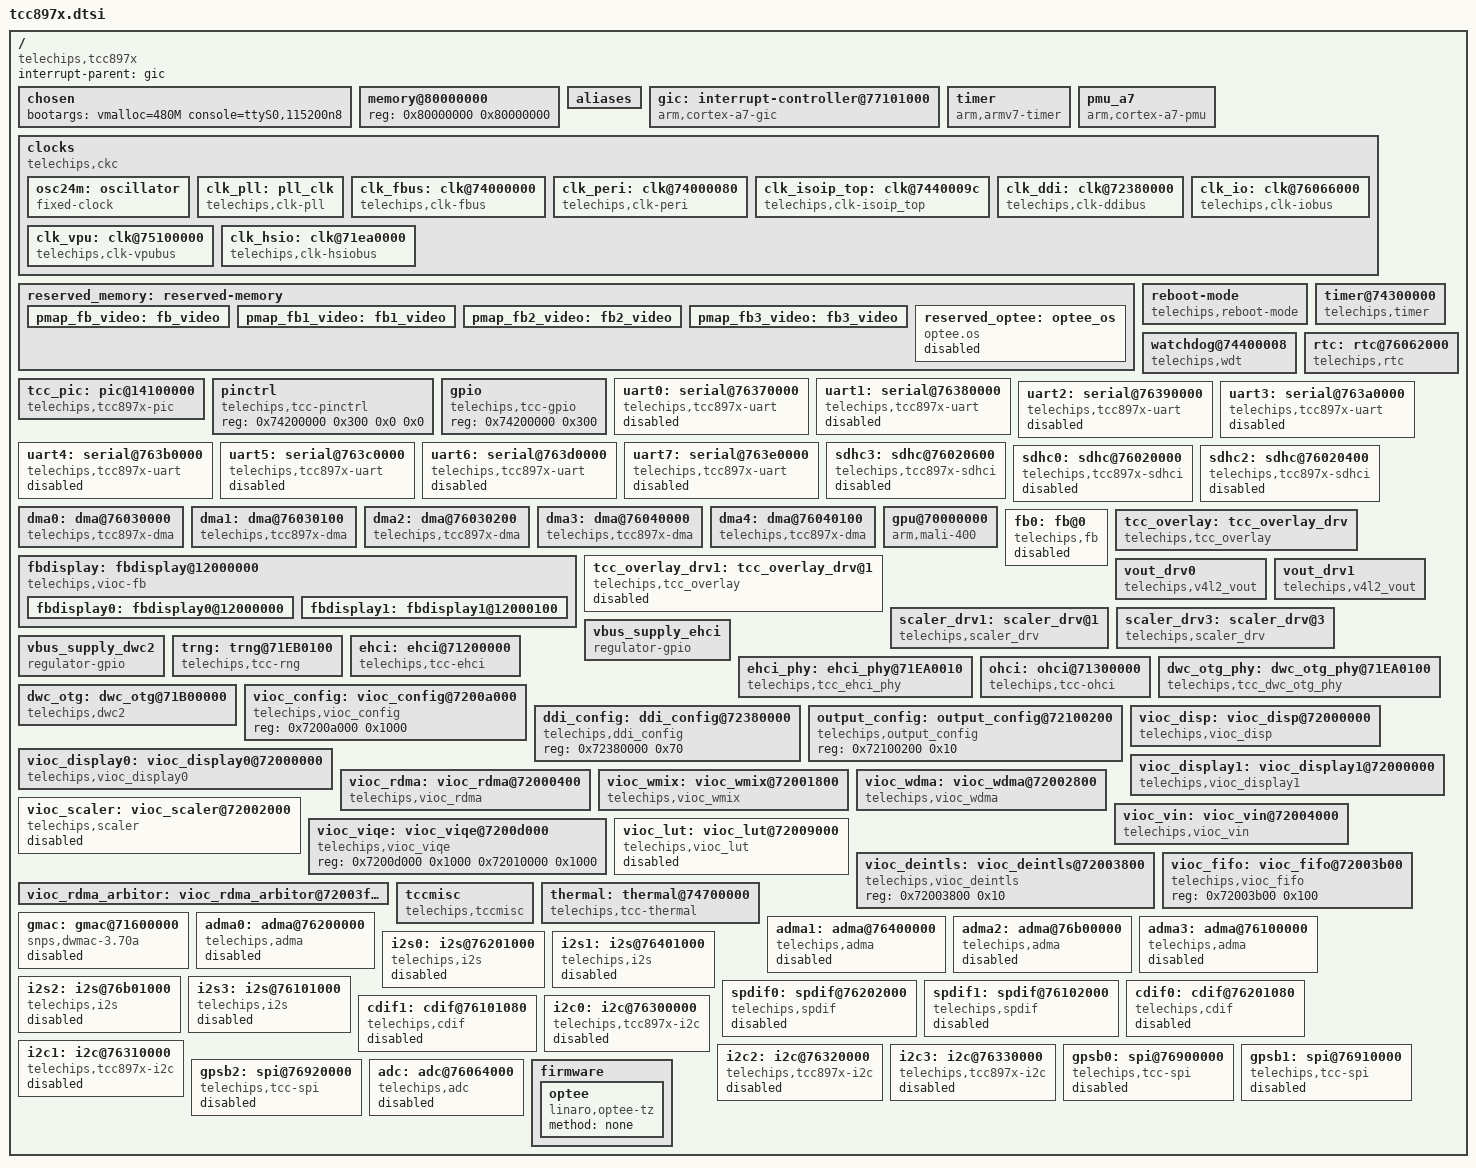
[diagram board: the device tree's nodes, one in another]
// SPDX-License-Identifier: (GPL-2.0-or-later OR MIT)
/*
 * Copyright (C) Telechips Inc.
 */

#include <dt-bindings/interrupt-controller/arm-gic.h>
#include <dt-bindings/clock/telechips,tcc897x-clks.h>
#include <dt-bindings/soc/tcc897x-pm.h>
#include <dt-bindings/display/tcc897x-vioc.h>
#include <dt-bindings/power/tcc897x,boot-mode.h>

/ {
	compatible = "telechips,tcc897x";
	interrupt-parent = <&gic>;
	#address-cells = <1>;
	#size-cells = <1>;

	chosen {
		bootargs = "vmalloc=480M console=ttyS0,115200n8";
	};

	memory@80000000 {
		#address-cells = <1>;
		#size-cells = <1>;
		device_type = "memory";
		reg = <0x80000000 0x80000000>;
	};

	aliases {
		serial0 = &uart0;
		serial1 = &uart1;
		serial2 = &uart2;
		serial3 = &uart3;
		serial4 = &uart4;
		serial5 = &uart5;
		serial6 = &uart6;
		serial7 = &uart7;
		sdhc0 = &sdhc0;
		sdhc2 = &sdhc2;
		sdhc3 = &sdhc3;
		scaler-drv1 = &scaler_drv1;
		scaler-drv3 = &scaler_drv3;
		tcc-overlay-drv1 = &tcc_overlay_drv1;
		vout-drv0 = &vout_drv0;
		vout-drv1 = &vout_drv1;
		dma0 = &dma0;
		dma1 = &dma1;
		dma2 = &dma2;
		dma3 = &dma3;
		dma4 = &dma4;
		fb0 = &fb0;
		adma0 = &adma0;
		adma1 = &adma1;
		adma2 = &adma2;
		adma3 = &adma3;
		i2s0 = &i2s0;
		i2s1 = &i2s1;
		i2s2 = &i2s2;
		i2s3 = &i2s3;
		spdif0 = &spdif0;
		spdif1 = &spdif1;
		cdif0 = &cdif0;
		cdif1 = &cdif1;
		gmac = &gmac;
		i2c0 = &i2c0;
		i2c1 = &i2c1;
		i2c2 = &i2c2;
		i2c3 = &i2c3;
		gpsb0 = &gpsb0;
		gpsb1 = &gpsb1;
		gpsb2 = &gpsb2;
		adc = &adc;
	};

	gic:interrupt-controller@77101000 {
		compatible = "arm,cortex-a7-gic";
		#interrupt-cells = <3>;
		#address-cells = <0>;
		interrupt-controller;
		reg = <0x77101000 0x1000>,
		      <0x77102000 0x1000>;
	};

	timer {
		compatible = "arm,armv7-timer";
		interrupts = <GIC_PPI 13 (GIC_CPU_MASK_SIMPLE(4) | IRQ_TYPE_LEVEL_LOW)>,
		             <GIC_PPI 14 (GIC_CPU_MASK_SIMPLE(4) | IRQ_TYPE_LEVEL_LOW)>,
		             <GIC_PPI 11 (GIC_CPU_MASK_SIMPLE(4) | IRQ_TYPE_LEVEL_LOW)>,
		             <GIC_PPI 10 (GIC_CPU_MASK_SIMPLE(4) | IRQ_TYPE_LEVEL_LOW)>;
		always-on;
	};

	pmu_a7 {
		compatible = "arm,cortex-a7-pmu";
		interrupts = <GIC_SPI 64 IRQ_TYPE_LEVEL_LOW>,
		             <GIC_SPI 65 IRQ_TYPE_LEVEL_LOW>,
		             <GIC_SPI 66 IRQ_TYPE_LEVEL_LOW>,
		             <GIC_SPI 67 IRQ_TYPE_LEVEL_LOW>;
	};

	clocks {
		compatible = "telechips,ckc";
		#address-cells = <1>;
		#size-cells = <1>;
		reg = <0x74000000 0x1A8	/* ckc */
		       0x74400000 0x114	/* pmu */
		       0x73810000 0x018	/* memory bus configutaion */
		       0x72380000 0x008	/* display bus configutaion */
		       0x70010000 0x008	/* graphic bus configutaion */
		       0x76066000 0x070	/* io bus configutaion */
		       0x75100000 0x008	/* video bus configutaion */
		       0x71EA0000 0x008	/* hsio bus configutaion */
		       >;
		ranges;

		osc24m: oscillator {
			compatible = "fixed-clock";
			#clock-cells = <0>;
			clock-frequency = <24000000>;
			clock-output-names = "osc24m";
		};

		clk_pll: pll_clk {
			compatible = "telechips,clk-pll";
			#clock-cells = <1>;
			clocks = <&osc24m>;
			clock-output-names = "pll0", "pll1", "pll2", "pll_cb",
					     "pll_mb";
		};

		clk_fbus: clk@74000000 {
			compatible = "telechips,clk-fbus";
			#clock-cells = <1>;
			clock-indices =
				<FBUS_CPU0>, <FBUS_CPU1>, <FBUS_MEM>, <FBUS_DDI>,
				<FBUS_GPU>, <FBUS_IO>, <FBUS_VBUS>, <FBUS_CODA>,
				<FBUS_HSIO>, <FBUS_SMU>, <FBUS_G2D>, <FBUS_CMBUS>,
				<FBUS_HEVC_VCE>, <FBUS_HEVC_VCPU>,
				<FBUS_HEVC_BPU>;
			clock-output-names =
				"fbus_cpu0", "fbus_cpu1", "fbus_mem", "fbus_ddi",
				"fbus_gpu", "fbus_io", "fbus_vbus", "fbus_coda",
				"fbus_hsio", "fbus_smu", "fbus_g2d", "fbus_cmbus",
				"fbus_hevc_vce", "fbus_hevc_vcpu",
				"fbus_hevc_bpu";
			telechips,clock-flags =
				<0>,	/* FBUS_CPU0 */
				<0>,	/* FBUS_CPU1 */
				<(CLK_SET_RATE_GATE | CLK_IGNORE_UNUSED)>,	/* FBUS_MEM */
				<(CLK_SET_RATE_GATE | CLK_IGNORE_UNUSED)>,	/* FBUS_DDI */
				<(CLK_SET_RATE_GATE | CLK_IGNORE_UNUSED)>,	/* FBUS_GPU */
				<(CLK_SET_RATE_GATE | CLK_IGNORE_UNUSED)>,	/* FBUS_IO */
				<(CLK_SET_RATE_GATE | CLK_IGNORE_UNUSED)>,	/* FBUS_VBUS */
				<(CLK_SET_RATE_GATE | CLK_IGNORE_UNUSED)>,	/* FBUS_CODA */
				<(CLK_SET_RATE_GATE | CLK_IGNORE_UNUSED)>,	/* FBUS_HSIO */
				<(CLK_SET_RATE_GATE | CLK_IGNORE_UNUSED)>,	/* FBUS_SMU */
				<(CLK_SET_RATE_GATE | CLK_IGNORE_UNUSED)>,	/* FBUS_G2D */
				<CLK_IGNORE_UNUSED>,	/* FBUS_CMBUS */
				<(CLK_SET_RATE_GATE | CLK_IGNORE_UNUSED)>,	/* FBUS_HEVC_VCE */
				<(CLK_SET_RATE_GATE | CLK_IGNORE_UNUSED)>,	/* FBUS_HEVC_VCPU */
				<(CLK_SET_RATE_GATE | CLK_IGNORE_UNUSED)>;	/* FBUS_HEVC_BPU */
		};

		clk_peri: clk@74000080 {
			compatible = "telechips,clk-peri";
			#clock-cells = <1>;
			clock-indices =
				<PERI_TCX>, <PERI_TCT>, <PERI_TCZ>, <PERI_LCD0>,
				<PERI_LCDSI0>, <PERI_LCD1>, <PERI_LCDSI1>,
				<PERI_LCDTIMER>, <PERI_USB_OTG>,
				<PERI_GMAC_PTP>, <PERI_GMAC>, <PERI_USB_OTG_ADP>,
				<PERI_IOB_CEC>, <PERI_OUT0>, <PERI_HDMI>,
				<PERI_HDMIA>, <PERI_OUT1>, <PERI_REMOTE>,
				<PERI_SDMMC0>, <PERI_SDMMC1>, <PERI_SDMMC2>,
				<PERI_SDMMC3>, <PERI_ADAI3>, <PERI_ADAM3>,
				<PERI_SPDIF3>, <PERI_ADAI0>, <PERI_ADAM0>,
				<PERI_SPDIF0>, <PERI_PDM>, <PERI_CMBUS_CNT>,
				<PERI_ADC>, <PERI_I2C0>, <PERI_I2C1>, <PERI_I2C2>,
				<PERI_I2C3>, <PERI_UART0>, <PERI_UART1>,
				<PERI_UART2>, <PERI_UART3>, <PERI_UART4>,
				<PERI_UART5>, <PERI_UART6>, <PERI_UART7>,
				<PERI_GPSB0>, <PERI_GPSB1>, <PERI_GPSB2>,
				<PERI_I2C6>, <PERI_I2C7>, <PERI_OUT2>, <PERI_OUT3>,
				<PERI_OUT4>, <PERI_OUT5>, <PERI_TSTX0>,
				<PERI_CMBUS_TSIF0>, <PERI_CMBUS_TSIF1>,
				<PERI_CMBUS_TSIF2>, <PERI_CMBUS_TSIF3>, <PERI_I2C4>,
				<PERI_I2C5>, <PERI_HDMI_PCLK>, <PERI_ADAI1>,
				<PERI_ADAM1>, <PERI_SPDIF1>, <PERI_ADAI2>,
				<PERI_ADAM2>, <PERI_SPDIF2>;
			clock-output-names =
				"peri_tcx", "peri_tct", "peri_tcz", "peri_lcd0",
				"peri_lcdsi0", "peri_lcd1", "peri_lcdsi1",
				"peri_lcdtimer", "peri_usb_otg",
				"peri_gmac_ptp", "peri_gmac", "peri_usb_otg_adp",
				"peri_iob_cec", "peri_out0", "peri_hdmi",
				"peri_hdmia", "peri_out1", "peri_remote",
				"peri_sdmmc0", "peri_sdmmc1", "peri_sdmmc2",
				"peri_sdmmc3", "peri_adai3", "peri_adam3",
				"peri_spdif3", "peri_adai0", "peri_adam0",
				"peri_spdif0", "peri_pdm", "peri_cmbus_cnt",
				"peri_adc", "peri_i2c0", "peri_i2c1", "peri_i2c2",
				"peri_i2c3", "peri_uart0", "peri_uart1",
				"peri_uart2", "peri_uart3", "peri_uart4",
				"peri_uart5", "peri_uart6", "peri_uart7",
				"peri_gpsb0", "peri_gpsb1", "peri_gpsb2",
				"peri_i2c6", "peri_i2c7", "peri_out2", "peri_out3",
				"peri_out4", "peri_out5", "peri_tstx0",
				"peri_cmbus_tsif0", "peri_cmbus_tsif1",
				"peri_cmbus_tsif2", "peri_cmbus_tsif3", "peri_i2c4",
				"peri_i2c5", "peri_hdmi_pclk", "peri_adai1",
				"peri_adam1", "peri_spdif1", "peri_adai2",
				"peri_adam2", "peri_spdif2";
			telechips,clock-flags =
				<0>,	/* PERI_TCX */
				<0>,	/* PERI_TCT */
				<CLK_IGNORE_UNUSED>,	/* PERI_TCZ */
				<0>,	/* PERI_LCD0 */
				<0>,	/* PERI_LCDSI0 */
				<0>,	/* PERI_LCD1 */
				<0>,	/* PERI_LCDSI1 */
				<0>,	/* PERI_LCDTIMER */
				<0>,	/* PERI_USB_OTG */
				<0>,	/* PERI_GMAC_PTP */
				<0>,	/* PERI_GMAC */
				<0>,	/* PERI_USB_OTG_ADP */
				<0>,	/* PERI_IOB_CEC */
				<0>,	/* PERI_OUT0 */
				<0>,	/* PERI_HDMI */
				<0>,	/* PERI_HDMIA */
				<0>,	/* PERI_OUT1 */
				<0>,	/* PERI_REMOTE */
				<0>,	/* PERI_SDMMC0 */
				<0>,	/* PERI_SDMMC1 */
				<0>,	/* PERI_SDMMC2 */
				<0>,	/* PERI_SDMMC3 */
				<0>,	/* PERI_ADAI3 */
				<0>,	/* PERI_ADAM3 */
				<0>,	/* PERI_SPDIF3 */
				<0>,	/* PERI_ADAI0 */
				<0>,	/* PERI_ADAM0 */
				<0>,	/* PERI_SPDIF0 */
				<0>,	/* PERI_PDM */
				<CLK_IGNORE_UNUSED>,	/* PERI_CMBUS_CNT */
				<0>,	/* PERI_ADC */
				<0>,	/* PERI_I2C0 */
				<0>,	/* PERI_I2C1 */
				<0>,	/* PERI_I2C2 */
				<0>,	/* PERI_I2C3 */
				<0>,	/* PERI_UART0 */
				<0>,	/* PERI_UART1 */
				<0>,	/* PERI_UART2 */
				<0>,	/* PERI_UART3 */
				<0>,	/* PERI_UART4 */
				<0>,	/* PERI_UART5 */
				<0>,	/* PERI_UART6 */
				<0>,	/* PERI_UART7 */
				<0>,	/* PERI_GPSB0 */
				<0>,	/* PERI_GPSB1 */
				<0>,	/* PERI_GPSB2 */
				<0>,	/* PERI_I2C6 */
				<0>,	/* PERI_I2C7 */
				<0>,	/* PERI_OUT2 */
				<0>,	/* PERI_OUT3 */
				<0>,	/* PERI_OUT4 */
				<0>,	/* PERI_OUT5 */
				<0>,	/* PERI_TSTX0 */
				<0>,	/* PERI_CMBUS_TSIF0 */
				<0>,	/* PERI_CMBUS_TSIF1 */
				<0>,	/* PERI_CMBUS_TSIF2 */
				<0>,	/* PERI_CMBUS_TSIF3 */
				<0>,	/* PERI_I2C4 */
				<0>,	/* PERI_I2C5 */
				<0>,	/* PERI_HDMI_PCLK */
				<CLK_IGNORE_UNUSED>,	/* PERI_ADAI1 */
				<CLK_IGNORE_UNUSED>,	/* PERI_ADAM1 */
				<0>,	/* PERI_SPDIF1 */
				<0>,	/* PERI_ADAI2 */
				<0>,	/* PERI_ADAM2 */
				<0>;	/* PERI_SPDIF2 */
		};

		clk_isoip_top: clk@7440009c {
			compatible = "telechips,clk-isoip_top";
			#clock-cells = <1>;
			clock-indices =
				<ISOIP_TOP_OTP>, <ISOIP_TOP_RTC>,
				<ISOIP_TOP_PLL>, <ISOIP_TOP_ECID>,
				<ISOIP_TOP_HDMI>, <ISOIP_TOP_VDAC_3CH>,
				<ISOIP_TOP_VDAC_1CH>, <ISOIP_TOP_TSADC>,
				<ISOIP_TOP_USB2P>, <ISOIP_TOP_USBOTG>,
				<ISOIP_TOP_LVDS>;
			clock-output-names =
				"isoip_top_otp", "isoip_top_rtc",
				"isoip_top_pll", "isoip_top_ecid",
				"isoip_top_hdmi", "isoip_top_vdac_3ch",
				"isoip_top_vdac_1ch", "isoip_top_tsadc",
				"isoip_top_usb2p", "isoip_top_usbotg",
				"isoip_top_lvds";
			telechips,clock-flags =
				<(CLK_SET_RATE_GATE | CLK_IGNORE_UNUSED)>,	/* ISOIP_TOP_OTP */
				<(CLK_SET_RATE_GATE | CLK_IGNORE_UNUSED)>,	/* ISOIP_TOP_RTC */
				<(CLK_SET_RATE_GATE | CLK_IGNORE_UNUSED)>,	/* ISOIP_TOP_PLL */
				<CLK_SET_RATE_GATE>,	/* ISOIP_TOP_ECID */
				<CLK_SET_RATE_GATE>,	/* ISOIP_TOP_HDMI */
				<CLK_SET_RATE_GATE>,	/* ISOIP_TOP_VDAC_3CH */
				<CLK_SET_RATE_GATE>,	/* ISOIP_TOP_VDAC_1CH */
				<CLK_SET_RATE_GATE>,	/* ISOIP_TOP_TSADC */
				<CLK_SET_RATE_GATE>,	/* ISOIP_TOP_USB2P */
				<CLK_SET_RATE_GATE>,	/* ISOIP_TOP_USBOTG */
				<CLK_SET_RATE_GATE>;	/* ISOIP_TOP_LVDS */
		};

		clk_ddi: clk@72380000 {
			compatible = "telechips,clk-ddibus";
			#clock-cells = <1>;
			clock-indices =
				<DDIBUS_VIOC>, <DDIBUS_NTSCPAL>, <DDIBUS_HDMI>,
				<DDIBUS_G2D>;
			clock-output-names =
				"ddibus_vioc", "ddibus_ntscpal", "ddibus_hdmi",
				"ddibus_g2d";
			telechips,clock-flags =
				<CLK_IGNORE_UNUSED>,	/* DDIBUS_VIOC */
				<CLK_IGNORE_UNUSED>,	/* DDIBUS_NTSCPAL */
				<CLK_IGNORE_UNUSED>,	/* DDIBUS_HDMI */
				<CLK_IGNORE_UNUSED>;	/* DDIBUS_G2D */
		};

		clk_io: clk@76066000 {
			compatible = "telechips,clk-iobus";
			#clock-cells = <1>;
			clock-indices =
				<IOBUS_SDMMC0>, <IOBUS_SDMMC2>, <IOBUS_SDMMC3>,
				<IOBUS_SDMMC>, <IOBUS_DMA0>, <IOBUS_DMA1>,
				<IOBUS_DMA2>, <IOBUS_DMA>, <IOBUS_PWM>, <IOBUS_SMC>,
				<IOBUS_I2C_S2>, <IOBUS_RTC>, <IOBUS_REMOCON>,
				<IOBUS_TSADC>, <IOBUS_EDICFG>, <IOBUS_EDI>,
				<IOBUS_PROT>, <IOBUS_ADMA0>, <IOBUS_DAI0>,
				<IOBUS_SPDIF0>, <IOBUS_AUDIO0>, <IOBUS_ADMA3>,
				<IOBUS_DAI3>, <IOBUS_SPDIF3>, <IOBUS_AUDIO3>,
				<IOBUS_I2C_M0>, <IOBUS_I2C_M1>, <IOBUS_I2C_M2>,
				<IOBUS_I2C_M3>, <IOBUS_I2C_S0>, <IOBUS_I2C_S1>,
				<IOBUS_I2C>, <IOBUS_UART0>, <IOBUS_UART1>,
				<IOBUS_UART2>, <IOBUS_UART3>, <IOBUS_UART4>,
				<IOBUS_UART5>, <IOBUS_UART6>, <IOBUS_UART7>,
				<IOBUS_UART>, <IOBUS_NFC>, <IOBUS_TS0>, <IOBUS_GPSB0>,
				<IOBUS_GPSB1>, <IOBUS_GPSB2>, <IOBUS_GPSB>,
				<IOBUS_CEC>, <IOBUS_I2C_S3>, <IOBUS_I2C_M4>,
				<IOBUS_I2C_M5>, <IOBUS_I2C_M6>, <IOBUS_I2C_M7>,
				<IOBUS_DMAC0>, <IOBUS_DMAC1>, <IOBUS_DMAC2>,
				<IOBUS_DMAC>, <IOBUS_ADMA1>, <IOBUS_DAI1>,
				<IOBUS_SPDIF1>, <IOBUS_AUDIO1>, <IOBUS_ADMA2>,
				<IOBUS_DAI2>, <IOBUS_SPDIF2>, <IOBUS_AUDIO2>;
			clock-output-names =
				"iobus_sdmmc0", "iobus_sdmmc2", "iobus_sdmmc3",
				"iobus_sdmmc", "iobus_dma0", "iobus_dma1",
				"iobus_dma2", "iobus_dma", "iobus_pwm", "iobus_smc",
				"iobus_i2c_s2", "iobus_rtc", "iobus_remocon",
				"iobus_tsadc", "iobus_edicfg", "iobus_edi",
				"iobus_prot", "iobus_adma0", "iobus_dai0",
				"iobus_spdif0", "iobus_audio0", "iobus_adma3",
				"iobus_dai3", "iobus_spdif3", "iobus_audio3",
				"iobus_i2c_m0", "iobus_i2c_m1", "iobus_i2c_m2",
				"iobus_i2c_m3", "iobus_i2c_s0", "iobus_i2c_s1",
				"iobus_i2c", "iobus_uart0", "iobus_uart1",
				"iobus_uart2", "iobus_uart3", "iobus_uart4",
				"iobus_uart5", "iobus_uart6", "iobus_uart7",
				"iobus_uart", "iobus_nfc", "iobus_ts0", "iobus_gpsb0",
				"iobus_gpsb1", "iobus_gpsb2", "iobus_gpsb",
				"iobus_cec", "iobus_i2c_s3", "iobus_i2c_m4",
				"iobus_i2c_m5", "iobus_i2c_m6", "iobus_i2c_m7",
				"iobus_dmac0", "iobus_dmac1", "iobus_dmac2",
				"iobus_dmac", "iobus_adma1", "iobus_dai1",
				"iobus_spdif1", "iobus_audio1", "iobus_adma2",
				"iobus_dai2", "iobus_spdif2", "iobus_audio2";
			telechips,clock-flags =
				<CLK_IGNORE_UNUSED>,	/* IOBUS_SDMMC0 */
				<CLK_IGNORE_UNUSED>,	/* IOBUS_SDMMC2 */
				<CLK_IGNORE_UNUSED>,	/* IOBUS_SDMMC3 */
				<CLK_IGNORE_UNUSED>,	/* IOBUS_SDMMC */
				<CLK_IGNORE_UNUSED>,	/* IOBUS_DMA0 */
				<CLK_IGNORE_UNUSED>,	/* IOBUS_DMA1 */
				<CLK_IGNORE_UNUSED>,	/* IOBUS_DMA2 */
				<CLK_IGNORE_UNUSED>,	/* IOBUS_DMA */
				<CLK_IGNORE_UNUSED>,	/* IOBUS_PWM */
				<CLK_IGNORE_UNUSED>,	/* IOBUS_SMC */
				<CLK_IGNORE_UNUSED>,	/* IOBUS_I2C_S2 */
				<CLK_IGNORE_UNUSED>,	/* IOBUS_RTC */
				<CLK_IGNORE_UNUSED>,	/* IOBUS_REMOCON */
				<CLK_IGNORE_UNUSED>,	/* IOBUS_TSADC */
				<CLK_IGNORE_UNUSED>,	/* IOBUS_EDICFG */
				<CLK_IGNORE_UNUSED>,	/* IOBUS_EDI */
				<CLK_IGNORE_UNUSED>,	/* IOBUS_PROT */
				<CLK_IGNORE_UNUSED>,	/* IOBUS_ADMA0 */
				<CLK_IGNORE_UNUSED>,	/* IOBUS_DAI0 */
				<CLK_IGNORE_UNUSED>,	/* IOBUS_SPDIF0 */
				<CLK_IGNORE_UNUSED>,	/* IOBUS_AUDIO0 */
				<CLK_IGNORE_UNUSED>,	/* IOBUS_ADMA3 */
				<CLK_IGNORE_UNUSED>,	/* IOBUS_DAI3 */
				<CLK_IGNORE_UNUSED>,	/* IOBUS_SPDIF3 */
				<CLK_IGNORE_UNUSED>,	/* IOBUS_AUDIO3 */
				<CLK_IGNORE_UNUSED>,	/* IOBUS_I2C_M0 */
				<CLK_IGNORE_UNUSED>,	/* IOBUS_I2C_M1 */
				<CLK_IGNORE_UNUSED>,	/* IOBUS_I2C_M2 */
				<CLK_IGNORE_UNUSED>,	/* IOBUS_I2C_M3 */
				<CLK_IGNORE_UNUSED>,	/* IOBUS_I2C_S0 */
				<CLK_IGNORE_UNUSED>,	/* IOBUS_I2C_S1 */
				<CLK_IGNORE_UNUSED>,	/* IOBUS_I2C */
				<CLK_IGNORE_UNUSED>,	/* IOBUS_UART0 */
				<CLK_IGNORE_UNUSED>,	/* IOBUS_UART1 */
				<CLK_IGNORE_UNUSED>,	/* IOBUS_UART2 */
				<CLK_IGNORE_UNUSED>,	/* IOBUS_UART3 */
				<CLK_IGNORE_UNUSED>,	/* IOBUS_UART4 */
				<CLK_IGNORE_UNUSED>,	/* IOBUS_UART5 */
				<CLK_IGNORE_UNUSED>,	/* IOBUS_UART6 */
				<CLK_IGNORE_UNUSED>,	/* IOBUS_UART7 */
				<CLK_IGNORE_UNUSED>,	/* IOBUS_UART */
				<CLK_IGNORE_UNUSED>,	/* IOBUS_NFC */
				<CLK_IGNORE_UNUSED>,	/* IOBUS_TS0 */
				<CLK_IGNORE_UNUSED>,	/* IOBUS_GPSB0 */
				<CLK_IGNORE_UNUSED>,	/* IOBUS_GPSB1 */
				<CLK_IGNORE_UNUSED>,	/* IOBUS_GPSB2 */
				<CLK_IGNORE_UNUSED>,	/* IOBUS_GPSB */
				<CLK_IGNORE_UNUSED>,	/* IOBUS_CEC */
				<CLK_IGNORE_UNUSED>,	/* IOBUS_I2C_S3 */
				<CLK_IGNORE_UNUSED>,	/* IOBUS_I2C_M4 */
				<CLK_IGNORE_UNUSED>,	/* IOBUS_I2C_M5 */
				<CLK_IGNORE_UNUSED>,	/* IOBUS_I2C_M6 */
				<CLK_IGNORE_UNUSED>,	/* IOBUS_I2C_M7 */
				<CLK_IGNORE_UNUSED>,	/* IOBUS_DMAC0 */
				<CLK_IGNORE_UNUSED>,	/* IOBUS_DMAC1 */
				<CLK_IGNORE_UNUSED>,	/* IOBUS_DMAC2 */
				<CLK_IGNORE_UNUSED>,	/* IOBUS_DMAC */
				<CLK_IGNORE_UNUSED>,	/* IOBUS_ADMA1 */
				<CLK_IGNORE_UNUSED>,	/* IOBUS_DAI1 */
				<CLK_IGNORE_UNUSED>,	/* IOBUS_SPDIF1 */
				<CLK_IGNORE_UNUSED>,	/* IOBUS_AUDIO1 */
				<CLK_IGNORE_UNUSED>,	/* IOBUS_ADMA2 */
				<CLK_IGNORE_UNUSED>,	/* IOBUS_DAI2 */
				<CLK_IGNORE_UNUSED>,	/* IOBUS_SPDIF2 */
				<CLK_IGNORE_UNUSED>;	/* IOBUS_AUDIO2 */
		};

		clk_vpu: clk@75100000 {
			compatible = "telechips,clk-vpubus";
			#clock-cells = <1>;
			clock-indices =
				<VIDEOBUS_JENC>, <VIDEOBUS_COD>,
				<VIDEOBUS_VBUS>, <VIDEOBUS_HEVC>;
			clock-output-names =
				"videobus_jenc", "videobus_cod",
				"videobus_vbus", "videobus_hevc";
			telechips,clock-flags =
				<CLK_IGNORE_UNUSED>,	/* VIDEOBUS_JENC */
				<CLK_IGNORE_UNUSED>,	/* VIDEOBUS_COD */
				<CLK_IGNORE_UNUSED>,	/* VIDEOBUS_VBUS */
				<CLK_IGNORE_UNUSED>;	/* VIDEOBUS_HEVC */
		};

		clk_hsio: clk@71ea0000 {
			compatible = "telechips,clk-hsiobus";
			#clock-cells = <1>;
			clock-indices =
				<HSIOBUS_USBOTG>, <HSIOBUS_GMAC>,
				<HSIOBUS_USB20H>, <HSIOBUS_CIPHER>, <HSIOBUS_TRNG>;
			clock-output-names =
				"hsiobus_usbotg", "hsiobus_gmac",
				"hsiobus_usb20h", "hsiobus_cipher", "hsiobus_trng";
			telechips,clock-flags =
				<CLK_IGNORE_UNUSED>,	/* HSIOBUS_USBOTG */
				<CLK_IGNORE_UNUSED>,	/* HSIOBUS_GMAC */
				<CLK_IGNORE_UNUSED>,	/* HSIOBUS_USB20H */
				<CLK_IGNORE_UNUSED>,	/* HSIOBUS_CIPHER */
				<CLK_IGNORE_UNUSED>;	/* HSIOBUS_TRNG */
		};
	};

	reserved_memory: reserved-memory {
		#address-cells = <1>;
		#size-cells = <1>;
		ranges;
		pmap_fb_video: fb_video {};
		pmap_fb1_video: fb1_video {};
		pmap_fb2_video: fb2_video {};
		pmap_fb3_video: fb3_video {};

		reserved_optee: optee_os {
			compatible = "optee.os";
			reg = <0x83400000 0x00C00000>;
			no-map;
			status = "disabled";
		};
	};

	reboot-mode {
		compatible = "telechips,reboot-mode";
		reg = <0x7440001c 0x4>;
		mode-normal = <BOOT_NORMAL>;
		mode-bootloader = <BOOT_FASTBOOT>;
		mode-recovery = <BOOT_RECOVERY>;
	};

	timer@74300000 { /* tc0 ~ tc5 */
		compatible = "telechips,timer";
		reg = <0x74300000 0x60 0x74300060 0x4>;
		interrupts = <GIC_SPI 0 IRQ_TYPE_LEVEL_HIGH>;
		clocks = <&clk_peri PERI_TCT>;
		clock-frequency = <12000000>;
	};

	watchdog@74400008 {
		compatible = "telechips,wdt";
		reg = <0x74400008 0x4>,	/* wdt_ctrl */
			  <0x74400008 0x4>,	/* wdt_cnt */
			  <0x74400008 0x4>,	/* wdt_clear */
			  <0x74300070 0xC>,	/* wdt_timer */
			  <0x74300060 0x4>;	/* wdt_int_sts */
		clocks = <&clk_peri PERI_TCX &clk_peri PERI_TCT>;
		clock-frequency = <366>; /* 24MHz / 65536 */
		interrupts = <GIC_SPI 0 IRQ_TYPE_LEVEL_HIGH>;
		int-offset = <6>;
		clear-bit = <30>;
	};

	tcc_pic: pic@14100000 {
		compatible = "telechips,tcc897x-pic";
		reg = <0x74100038 0x0008>,  /* pol_0_base */
		      <0x74100038 0x0008>,  /* pol_1_base */
		      <0x0 0x0>,            /* cmb_cm4_base */
		      <0x0 0x0>,            /* strgb_cm4_base */
		      <0x0 0x0>;            /* ca7_irqo_en_base */
		demarcation = <64>;
		max_irq = <64>;
	};


	pinctrl: pinctrl {
		compatible = "telechips,tcc-pinctrl";
		reg = <0x74200000 0x300 0x0 0x0>;
	};

	gpio: gpio {
		compatible = "telechips,tcc-gpio";
		reg = <0x74200000 0x300>;
	};

	rtc: rtc@76062000 {
		compatible = "telechips,rtc";
		reg = <0x76062000 0x50>;
		clocks = <&clk_io IOBUS_RTC &clk_isoip_top ISOIP_TOP_RTC>;
		interrupts = <GIC_SPI 43 IRQ_TYPE_LEVEL_HIGH>;
	};

	uart0: serial@76370000 {
		compatible = "telechips,tcc897x-uart";
		reg = <0x76370000 0x84>;
		interrupt-parent = <&gic>;
		interrupts = <GIC_SPI 47 IRQ_TYPE_LEVEL_HIGH>;
		clocks = <&clk_io IOBUS_UART0 &clk_peri PERI_UART0>;
		status = "disabled";
	};

	uart1: serial@76380000 {
		compatible = "telechips,tcc897x-uart";
		reg = <0x76380000 0x84>;
		interrupt-parent = <&gic>;
		interrupts = <GIC_SPI 47 IRQ_TYPE_LEVEL_HIGH>;
		clocks = <&clk_io IOBUS_UART1 &clk_peri PERI_UART1>;
		status = "disabled";
	};

	uart2: serial@76390000 {
		compatible = "telechips,tcc897x-uart";
		reg = <0x76390000 0x84>;
		interrupt-parent = <&gic>;
		interrupts = <GIC_SPI 47 IRQ_TYPE_LEVEL_HIGH>;
		clocks = <&clk_io IOBUS_UART2 &clk_peri PERI_UART2>;
		status = "disabled";
	};

	uart3: serial@763a0000 {
		compatible = "telechips,tcc897x-uart";
		reg = <0x763a0000 0x84>;
		interrupt-parent = <&gic>;
		interrupts = <GIC_SPI 47 IRQ_TYPE_LEVEL_HIGH>;
		clocks = <&clk_io IOBUS_UART3 &clk_peri PERI_UART3>;
		status = "disabled";
	};

	uart4: serial@763b0000 {
		compatible = "telechips,tcc897x-uart";
		reg = <0x763b0000 0x84>;
		interrupt-parent = <&gic>;
		interrupts = <GIC_SPI 47 IRQ_TYPE_LEVEL_HIGH>;
		clocks = <&clk_io IOBUS_UART4 &clk_peri PERI_UART4>;
		status = "disabled";
	};

	uart5: serial@763c0000 {
		compatible = "telechips,tcc897x-uart";
		reg = <0x763c0000 0x84>;
		interrupt-parent = <&gic>;
		interrupts = <GIC_SPI 47 IRQ_TYPE_LEVEL_HIGH>;
		clocks = <&clk_io IOBUS_UART5 &clk_peri PERI_UART5>;
		status = "disabled";
	};

	uart6: serial@763d0000 {
		compatible = "telechips,tcc897x-uart";
		reg = <0x763d0000 0x84>;
		interrupt-parent = <&gic>;
		interrupts = <GIC_SPI 47 IRQ_TYPE_LEVEL_HIGH>;
		clocks = <&clk_io IOBUS_UART6 &clk_peri PERI_UART6>;
		status = "disabled";
	};

	uart7: serial@763e0000 {
		compatible = "telechips,tcc897x-uart";
		reg = <0x763e0000 0x84>;
		interrupt-parent = <&gic>;
		interrupts = <GIC_SPI 47 IRQ_TYPE_LEVEL_HIGH>;
		clocks = <&clk_io IOBUS_UART7 &clk_peri PERI_UART7>;
		status = "disabled";
	};

	sdhc3: sdhc@76020600 {
		compatible = "telechips,tcc897x-sdhci";
		reg = <0x76020600 0x100>, <0x76020800 0x80>;
		interrupts = <GIC_SPI 32 IRQ_TYPE_LEVEL_HIGH>;
		clocks = <&clk_peri PERI_SDMMC3 &clk_io IOBUS_SDMMC3>;
		clock-names = "mmc_fclk", "mmc_hclk";
		max-frequency = <48000000>;
		/*cap-sd-highspeed;*/
		/*cap-mmc-highspeed;*/
		bus-width = <4>;
		status = "disabled";
	};

	sdhc0: sdhc@76020000 {
		compatible = "telechips,tcc897x-sdhci";
		reg = <0x76020000 0x100>, <0x76020800 0x80>;
		interrupts = <GIC_SPI 44 IRQ_TYPE_LEVEL_HIGH>;
		clocks = <&clk_peri PERI_SDMMC0 &clk_io IOBUS_SDMMC0>;
		clock-names = "mmc_fclk", "mmc_hclk";
		max-frequency = <48000000>;
		/*cap-sd-highspeed;*/
		/*cap-mmc-highspeed;*/
		bus-width = <4>;
		status = "disabled";
	};

	sdhc2: sdhc@76020400 {
		compatible = "telechips,tcc897x-sdhci";
		reg = <0x76020400 0x100>, <0x76020800 0x80>;
		interrupts = <GIC_SPI 33 IRQ_TYPE_LEVEL_HIGH>;
		clocks = <&clk_peri PERI_SDMMC2 &clk_io IOBUS_SDMMC2>;
		clock-names = "mmc_fclk", "mmc_hclk";
		max-frequency = <48000000>;
		/*cap-sd-highspeed;*/
		/*cap-mmc-highspeed;*/
		bus-width = <4>;
		status = "disabled";
	};


	dma0: dma@76030000 {
		compatible = "telechips,tcc897x-dma";
		reg = <0x76030000 0x94>, /* base address */
		      <0x76066004 0x04>; /* DMAREQSEL0 */
		interrupts = <GIC_SPI 29 IRQ_TYPE_LEVEL_HIGH>;
		#dma-cells = <2>;
		dma-channels = <3>;
		dma-requests = <32>;
		channel-priority = <0>;
		clocks = <&clk_io IOBUS_DMA0>;
		clock-names = "dmac0";
	};

	dma1: dma@76030100 {
		compatible = "telechips,tcc897x-dma";
		reg = <0x76030100 0x94>, /* base address */
		      <0x76066008 0x04>; /* DMAREQSEL0 */
		interrupts = <GIC_SPI 29 IRQ_TYPE_LEVEL_HIGH>;
		#dma-cells = <2>;
		dma-channels = <3>;
		dma-requests = <32>;
		channel-priority = <0>;
		clocks = <&clk_io IOBUS_DMA1>;
		clock-names = "dmac1";
	};

	dma2: dma@76030200 {
		compatible = "telechips,tcc897x-dma";
		reg = <0x76030200 0x94>, /* base address */
		      <0x7606600C 0x04>; /* DMAREQSEL0 */
		interrupts = <GIC_SPI 29 IRQ_TYPE_LEVEL_HIGH>;
		#dma-cells = <2>;
		dma-channels = <3>;
		dma-requests = <32>;
		channel-priority = <0>;
		clocks = <&clk_io IOBUS_DMA2>;
		clock-names = "dmac2";
	};

	dma3: dma@76040000 {
		compatible = "telechips,tcc897x-dma";
		reg = <0x76040000 0x94>, /* base address */
		      <0x76066060 0x04>; /* DMAREQSEL0 */
		interrupts = <GIC_SPI 96 IRQ_TYPE_LEVEL_HIGH>;
		#dma-cells = <2>;
		dma-channels = <3>;
		dma-requests = <32>;
		channel-priority = <0>;
		clocks = <&clk_io IOBUS_DMAC0>;
		clock-names = "dmac3";
	};

	dma4: dma@76040100 {
		compatible = "telechips,tcc897x-dma";
		reg = <0x76040100 0x94>, /* base address */
		      <0x76066064 0x04>; /* DMAREQSEL0 */
		interrupts = <GIC_SPI 96 IRQ_TYPE_LEVEL_HIGH>;
		#dma-cells = <2>;
		dma-channels = <3>;
		dma-requests = <32>;
		channel-priority = <0>;
		clocks = <&clk_io IOBUS_DMAC1>;
		clock-names = "dmac4";
	};

	gpu@70000000 {
		compatible = "arm,mali-400", "arm,mali-utgard";
		reg = <0x70000000 0x10000>;
		interrupts =
			<GIC_SPI 25 IRQ_TYPE_LEVEL_HIGH>,
			<GIC_SPI 17 IRQ_TYPE_LEVEL_HIGH>,
			<GIC_SPI 24 IRQ_TYPE_LEVEL_HIGH>,
			<GIC_SPI 16 IRQ_TYPE_LEVEL_HIGH>,
			<GIC_SPI 35 IRQ_TYPE_LEVEL_HIGH>,
			<GIC_SPI 40 IRQ_TYPE_LEVEL_HIGH>,
			<GIC_SPI 26 IRQ_TYPE_LEVEL_HIGH>;
		interrupt-names =
			"IRQGP", "IRQGPMMU", "IRQPP0", "IRQPPMMU0",
			"IRQPP1", "IRQPPMMU1", "IRQPMU";
		shared_mem_size = <512>;
		clocks = <&clk_fbus FBUS_GPU>;
		clock-names = "mali_clk";
	};

	fbdisplay: fbdisplay@12000000 {
		compatible = "telechips,vioc-fb";
		reg = <0x0 0x12000000 0x0 0x10000>;
		telechips,fbdisplay_num = <0>;
		telechips,rdma_arbitor=<&vioc_rdma_arbitor>;
		memory-region = <&pmap_fb_video &pmap_fb1_video>;

		fbdisplay0:fbdisplay0@12000000{
			telechips,disp = <&vioc_disp VIOC_DISP0>;
			telechips,wmixer = <&vioc_wmix VIOC_WMIX0>;
			telechips,rdma = <&vioc_rdma VIOC_RDMA00 VIOC_RDMA01 VIOC_RDMA02 VIOC_RDMA03>;
			telechips,wdma = <&vioc_wdma VIOC_WDMA00>;
		};

		fbdisplay1:fbdisplay1@12000100{
			telechips,disp = <&vioc_disp VIOC_DISP1>;
			telechips,wmixer = <&vioc_wmix VIOC_WMIX1>;
			telechips,rdma = <&vioc_rdma VIOC_RDMA04 VIOC_RDMA05 VIOC_RDMA06 VIOC_RDMA07>;
			telechips,wdma = <&vioc_wdma VIOC_WDMA01>;
		};
	};

	fb0: fb@0 {
		#address-cells = <1>;
		#size-cells = <0>;
		compatible = "telechips,fb";
		status = "disable";
		memory-region = <&pmap_fb_video>;
		xres = <1024>;
		yres = <600>;
		bpp = <32>;
		chroma-key = <0x0 0x0 0x0>;
		chroma-mkey = <0xF8 0xFC 0xF8>;
		mode = <FBX_TRIPLE>;
		update-type = <FBX_RDMA_UPDATE>;
		device-priority = <FBX_DEVICE_LVDS>;
		telechips,disp = <&vioc_disp VIOC_DISP0>;
		telechips,wmixer = <&vioc_wmix VIOC_WMIX0>;
		telechips,rdma = <&vioc_rdma VIOC_RDMA00>;
	};

	tcc_overlay: tcc_overlay_drv {
		compatible = "telechips,tcc_overlay";
		fbdisplay-overlay = <&fbdisplay>;
		rdmas = <&vioc_rdma VIOC_RDMA00 VIOC_RDMA01 VIOC_RDMA02 VIOC_RDMA03 VIOC_RDMA04 VIOC_RDMA05 VIOC_RDMA06 VIOC_RDMA07>;
		wmixs = <&vioc_wmix VIOC_WMIX0 VIOC_WMIX1>;
		status = "okay";
	};

	tcc_overlay_drv1: tcc_overlay_drv@1 {
		compatible = "telechips,tcc_overlay";
		display_num = <0>;
		rdmas = <&vioc_rdma VIOC_RDMA00 VIOC_RDMA01 VIOC_RDMA02 VIOC_RDMA03 VIOC_RDMA04 VIOC_RDMA05 VIOC_RDMA06 VIOC_RDMA07>;
		wmixs = <&vioc_wmix VIOC_WMIX0 VIOC_WMIX1>;
		rdma_init_layer = <2>;
		status = "disabled";
	};

	vout_drv0: vout_drv0 {
	    compatible = "telechips,v4l2_vout";

	    reg = <0x0 0x0>;						/* Dummy regs. */
	    clocks = <&clk_ddi DDIBUS_VIOC>;

	    rdma = <&vioc_rdma VIOC_RDMA03>;
	    wmix = <&vioc_wmix VIOC_WMIX0>;
	    disp = <&vioc_disp VIOC_DISP0>;

	    subplane_rdma = <&vioc_rdma VIOC_RDMA02>;
	    m2m_subplane_rdma = <&vioc_rdma VIOC_RDMA05>;
	    m2m_rdma = <&vioc_rdma VIOC_RDMA07>;
	    m2m_wmix	= <&vioc_wmix VIOC_WMIX1>;
	    m2m_wdma = <&vioc_wdma VIOC_WDMA01>;

	    deintl_block = <&vioc_viqe VIOC_VIQE0>;
	    scaler = <&vioc_scaler VIOC_SCALER1>;

	    status = "okay";
	};

	vout_drv1: vout_drv1 {
	    compatible = "telechips,v4l2_vout";
	    reg = <0x1 0x0>;						/* Dummy regs. */
	    clocks = <&clk_ddi DDIBUS_VIOC>;

	    rdma = <&vioc_rdma VIOC_RDMA07>;
	    wmix = <&vioc_wmix VIOC_WMIX1>;
	    disp = <&vioc_disp VIOC_DISP1>;

	    subplane_rdma = <&vioc_rdma VIOC_RDMA05>;
	    m2m_subplane_rdma = <&vioc_rdma VIOC_RDMA13>;
	    m2m_rdma = <&vioc_rdma VIOC_RDMA12>;
	    m2m_wmix	= <&vioc_wmix VIOC_WMIX3>;
	    m2m_wdma = <&vioc_wdma VIOC_WDMA03>;

	    deintl_block = <&vioc_deintls VIOC_DEINTLS0>;
	    scaler = <&vioc_scaler VIOC_SCALER3>;

	    status = "okay";
	};

	/*
	 * Misc. Devices
	 */
	scaler_drv1: scaler_drv@1 {
		compatible = "telechips,scaler_drv";
		reg = <0x1 0x0>;
		clocks = <&clk_ddi DDIBUS_VIOC>;
		rdmas = <&vioc_rdma VIOC_RDMA15>;
		scalers = <&vioc_scaler VIOC_SCALER1>;
		wmixs = <&vioc_wmix VIOC_WMIX4>;
		wdmas = <&vioc_wdma VIOC_WDMA04>;
		settop_support = <0>;
		status = "okay";
	};

	scaler_drv3: scaler_drv@3 {
		compatible = "telechips,scaler_drv";
		reg = <0x3 0x0>;
		clocks = <&clk_ddi DDIBUS_VIOC>;
		rdmas = <&vioc_rdma VIOC_RDMA07>;
		scalers = <&vioc_scaler VIOC_SCALER3>;
		wmixs = <&vioc_wmix VIOC_WMIX1>;	/* id:1, path:2 */
		wdmas = <&vioc_wdma VIOC_WDMA01>;
		settop_support = <0>;
		status = "okay";
	};

	vbus_supply_ehci: vbus_supply_ehci {
		compatible = "regulator-gpio";
		regulator-name = "vbus_supply_ehci";
		regulator-type = "voltage";
		regulator-min-microvolt = <0000001>;
		regulator-max-microvolt = <5000000>;
		gpios-states = <0x0>;
		states = <0000001 0x0 5000000 0x1>;
	};

	vbus_supply_dwc2: vbus_supply_dwc2 {
		compatible = "regulator-gpio";
		regulator-name = "vbus_supply_dwc2";
		regulator-type = "voltage";
		regulator-min-microvolt = <0000001>;
		regulator-max-microvolt = <5000000>;
		gpios-states = <0x0>;
		states = <0000001 0x0 5000000 0x1>;
	};

	trng: trng@71EB0100 {
		compatible = "telechips,tcc-rng";
		reg = <0x71EB0100 0x100>;
		clocks = <&clk_hsio HSIOBUS_TRNG>;
		status = "okay";
	};

	ehci_phy: ehci_phy@71EA0010 {
		compatible = "telechips,tcc_ehci_phy";
		reg = <0x71EA0010 0x30>;
		interrupts = <GIC_SPI 49 IRQ_TYPE_LEVEL_HIGH>;
		vbus-supply = <&vbus_supply_ehci>;
		vbus-ctrl-able;
	};

	ehci: ehci@71200000 {
		compatible = "telechips,tcc-ehci";
		reg = <0x71200000 0x1000 0x71EA0010 0x1000>;
		interrupts = <GIC_SPI 49 IRQ_TYPE_LEVEL_HIGH>;
		telechips,ehci_phy = <&ehci_phy>;
		tpl-support;
	};

	ohci: ohci@71300000 {
		compatible = "telechips,tcc-ohci";
		reg = <0x71300000 0x1000 0x71EA0010 0x1000>;
		interrupts = <GIC_SPI 49 IRQ_TYPE_LEVEL_HIGH>;
		tpl-support;
	};

	dwc_otg_phy: dwc_otg_phy@71EA0100 {
		compatible = "telechips,tcc_dwc_otg_phy";
		reg = <0x71EA0100 0x20>;
		interrupts = <GIC_SPI 48 IRQ_TYPE_LEVEL_HIGH>;
		vbus-supply = <&vbus_supply_dwc2>;
		vbus-ctrl-able;
	};

	dwc_otg: dwc_otg@71B00000 {
		compatible = "telechips,dwc2";
		reg = <0x71B00000 0xCFFF 0x71EA0100 0x20>;
		interrupts = <GIC_SPI 48 IRQ_TYPE_LEVEL_HIGH>;
		phy = <&dwc_otg_phy>;
	};

	/*
	 * Display Bus Block
	 */
	vioc_config:vioc_config@7200a000{
		compatible = "telechips,vioc_config";
		reg = <0x7200a000 0x1000>;
	};

	ddi_config: ddi_config@72380000 {
		compatible = "telechips,ddi_config";
		reg = <0x72380000 0x70>;
	};

	output_config: output_config@72100200 {
		compatible = "telechips,output_config";
		reg = <0x72100200 0x10>;
	};

	vioc_disp:vioc_disp@72000000{
		compatible = "telechips,vioc_disp";
		reg = <0x72000000 0x100 0x72000100 0x100>;
		interrupts = <GIC_SPI 20 IRQ_TYPE_LEVEL_HIGH>, <GIC_SPI 20 IRQ_TYPE_LEVEL_HIGH>;
		clocks = <&clk_ddi DDIBUS_VIOC>, <&clk_peri PERI_LCD0>, <&clk_peri PERI_LCD1>;
		clock-names = "ddi-clk", "disp0-clk", "disp1-clk";
	};

	vioc_display0:vioc_display0@72000000{
		compatible = "telechips,vioc_display0";
		reg = <0x72000000 0x100>;
		interrupts = <GIC_SPI 20 IRQ_TYPE_LEVEL_HIGH>;
		clocks = <&clk_ddi DDIBUS_VIOC &clk_peri PERI_LCD0>;
		disp_number = <0>;
	};

	vioc_display1:vioc_display1@72000000{
		compatible = "telechips,vioc_display1";
		reg = <0x72000100 0x100>;
		interrupts = <GIC_SPI 20 IRQ_TYPE_LEVEL_HIGH>;
		clocks = <&clk_ddi DDIBUS_VIOC &clk_peri PERI_LCD1>;
		disp_number = <1>;
	};

	vioc_rdma:vioc_rdma@72000400{
		compatible = "telechips,vioc_rdma";
		reg = <0x72000400 0x100 0x72000500 0x100 0x72000600 0x100 0x72000700 0x100
		       0x72000800 0x100 0x72000900 0x100 0x72000a00 0x100 0x72000b00 0x100
		       0x72000c00 0x100 0x72000d00 0x100 0x72000e00 0x100 0x72000f00 0x100
		       0x72001000 0x100 0x72001100 0x100 0x72001200 0x100 0x72001300 0x100
		       0x72001400 0x100 0x72001500 0x100>;
		interrupts = <GIC_SPI 20 IRQ_TYPE_LEVEL_HIGH>,
		             <GIC_SPI 20 IRQ_TYPE_LEVEL_HIGH>,
		             <GIC_SPI 20 IRQ_TYPE_LEVEL_HIGH>,
		             <GIC_SPI 20 IRQ_TYPE_LEVEL_HIGH>,
		             <GIC_SPI 20 IRQ_TYPE_LEVEL_HIGH>,
		             <GIC_SPI 20 IRQ_TYPE_LEVEL_HIGH>,
		             <GIC_SPI 20 IRQ_TYPE_LEVEL_HIGH>,
		             <GIC_SPI 20 IRQ_TYPE_LEVEL_HIGH>,
		             <GIC_SPI 20 IRQ_TYPE_LEVEL_HIGH>,
		             <GIC_SPI 20 IRQ_TYPE_LEVEL_HIGH>,
		             <GIC_SPI 20 IRQ_TYPE_LEVEL_HIGH>,
		             <GIC_SPI 20 IRQ_TYPE_LEVEL_HIGH>,
		             <GIC_SPI 20 IRQ_TYPE_LEVEL_HIGH>,
		             <GIC_SPI 20 IRQ_TYPE_LEVEL_HIGH>,
		             <GIC_SPI 20 IRQ_TYPE_LEVEL_HIGH>,
		             <GIC_SPI 20 IRQ_TYPE_LEVEL_HIGH>,
		             <GIC_SPI 20 IRQ_TYPE_LEVEL_HIGH>,
		             <GIC_SPI 20 IRQ_TYPE_LEVEL_HIGH>;
	};

	vioc_wmix:vioc_wmix@72001800{
		compatible = "telechips,vioc_wmix";
		reg = <0x72001800 0x100 0x72001900 0x100 0x72001a00 0x100 0x72001b00 0x100
				0x72001c00 0x100 0x72001d00 0x100 0x72001e00 0x100>;
		interrupts = <GIC_SPI 20 IRQ_TYPE_LEVEL_HIGH>,
		             <GIC_SPI 20 IRQ_TYPE_LEVEL_HIGH>,
		             <GIC_SPI 20 IRQ_TYPE_LEVEL_HIGH>,
		             <GIC_SPI 20 IRQ_TYPE_LEVEL_HIGH>,
		             <GIC_SPI 20 IRQ_TYPE_LEVEL_HIGH>,
		             <GIC_SPI 20 IRQ_TYPE_LEVEL_HIGH>,
		             <GIC_SPI 20 IRQ_TYPE_LEVEL_HIGH>;
	};

	vioc_scaler:vioc_scaler@72002000{
		compatible = "telechips,scaler";
		reg = <0x72002000 0x100 0x72002100 0x100 0x72002200 0x100 0x72002300 0x100>;
		status = "disabled";
	};

	vioc_wdma:vioc_wdma@72002800{
		compatible = "telechips,vioc_wdma";
		reg = <0x72002800 0x700 0x72002900 0x100 0x72002a00 0x100 0x72002b00 0x100
		       0x72002c00 0x100 0x72002d00 0x100 0x72002e00 0x100 0x72002f00 0x100
		       0x72003000 0x100 >;
		interrupts = <GIC_SPI 20 IRQ_TYPE_LEVEL_HIGH>,
		             <GIC_SPI 20 IRQ_TYPE_LEVEL_HIGH>,
		             <GIC_SPI 20 IRQ_TYPE_LEVEL_HIGH>,
		             <GIC_SPI 20 IRQ_TYPE_LEVEL_HIGH>,
		             <GIC_SPI 20 IRQ_TYPE_LEVEL_HIGH>,
		             <GIC_SPI 20 IRQ_TYPE_LEVEL_HIGH>,
		             <GIC_SPI 20 IRQ_TYPE_LEVEL_HIGH>,
		             <GIC_SPI 20 IRQ_TYPE_LEVEL_HIGH>,
		             <GIC_SPI 20 IRQ_TYPE_LEVEL_HIGH>;
	};

	vioc_vin:vioc_vin@72004000{
		compatible = "telechips,vioc_vin";
		reg = < 0x72004000 0x400 0x72004400 0x600
			0x72005000 0x400 0x72005400 0x600
			0x72006000 0x400 0x72006400 0x600
			0x72007000 0x400 0x72007400 0x600>;
		interrupts = <GIC_SPI 20 IRQ_TYPE_LEVEL_HIGH>,
		             <GIC_SPI 20 IRQ_TYPE_LEVEL_HIGH>,
		             <GIC_SPI 20 IRQ_TYPE_LEVEL_HIGH>,
		             <GIC_SPI 20 IRQ_TYPE_LEVEL_HIGH>,
		             <GIC_SPI 20 IRQ_TYPE_LEVEL_HIGH>,
		             <GIC_SPI 20 IRQ_TYPE_LEVEL_HIGH>,
		             <GIC_SPI 20 IRQ_TYPE_LEVEL_HIGH>,
		             <GIC_SPI 20 IRQ_TYPE_LEVEL_HIGH>,
		             <GIC_SPI 20 IRQ_TYPE_LEVEL_HIGH>;
	};

	vioc_viqe:vioc_viqe@7200d000{
		compatible = "telechips,vioc_viqe";
		reg = <0x7200d000 0x1000 0x72010000 0x1000>;
	};

	vioc_lut:vioc_lut@72009000{
		compatible = "telechips,vioc_lut";
		reg = <0x72009000 0x800>;
		dev_max = <1>; /* 0: DEV0, 1: DEV1 and 2: DEV2 */
		vioc_max = <4>; /* 3: VIOC_LUT0, 4: VIOC_LUT1, 5: VIOC_LUT2 and 6: VIOC_LUT3 */
		status = "disabled";
	};

	vioc_deintls:vioc_deintls@72003800{
		compatible = "telechips,vioc_deintls";
		reg = <0x72003800 0x10>;
	};

	vioc_fifo:vioc_fifo@72003b00{
		compatible = "telechips,vioc_fifo";
		reg = <0x72003b00 0x100>;
	};

	vioc_rdma_arbitor:vioc_rdma_arbitor@72003f00{
		reg = <0x72003f00 0x20 0x72003f20 0x20 0x72003f40 0x20 0x72003f60 0x20>;
		arbitor_num = <4>;
	};

	tccmisc:tccmisc {
		/* Only use kernel-5.4 or up */
		compatible = "telechips,tccmisc";
		status = "okay";
	};

	thermal: thermal@74700000 {
		compatible = "telechips,tcc-thermal";
		reg = <0x74700000 0x160>;
		status = "okay";
		cal_type = "TYPE_ONE_POINT_TRIMMING";
		threshold_temp = <85>;
		#thermal-sensor-cells = <1>;
	};

	gmac: gmac@71600000 {
		compatible = "snps,dwmac-3.70a","telechips,gmac";
		reg = <0x71600000 0x3000>, <0x71EA0054 0x010>;
		interrupts = <GIC_SPI 50 IRQ_TYPE_LEVEL_HIGH>;
		status = "disabled";
		index = <1>;
		clocks = <&clk_peri PERI_GMAC &clk_fbus FBUS_HSIO &clk_peri PERI_GMAC_PTP &clk_hsio HSIOBUS_GMAC>; //PERI_GMAC0, HSIOBUS, PERI_PTP0, HCLK_GMAC
		clock-names = "gmac-pclk", "hsio-clk", "ptp-pclk", "gmac-hclk";
	};

	adma0: adma@76200000{
		compatible = "telechips,adma";
		reg = <0x76200000 0x200>;
		interrupts = <GIC_SPI 60 IRQ_TYPE_LEVEL_HIGH>;
		status = "disabled";
	};

	adma1: adma@76400000{
		compatible = "telechips,adma";
		reg = <0x76400000 0x200>;
		interrupts = <GIC_SPI 97 IRQ_TYPE_LEVEL_HIGH>;
		status = "disabled";
	};

	adma2: adma@76b00000{
		compatible = "telechips,adma";
		reg = <0x76b00000 0x200>;
		interrupts = <GIC_SPI 99 IRQ_TYPE_LEVEL_HIGH>;
		status = "disabled";
	};

	adma3: adma@76100000{
		compatible = "telechips,adma";
		reg = <0x76100000 0x200>;
		interrupts = <GIC_SPI 58 IRQ_TYPE_LEVEL_HIGH>;
		status = "disabled";
	};

	i2s0: i2s@76201000 {
		compatible = "telechips,i2s";
		reg = <0x76201000 0x50>;
		clocks = <&clk_peri PERI_ADAI0 &clk_io IOBUS_DAI0>;
		clock-frequency = <11289600>;   // 44100*256
		adma = <&adma0>;
		status = "disabled";
	};

	i2s1: i2s@76401000 {
		compatible = "telechips,i2s";
		reg = <0x76401000 0x50>;
		clocks = <&clk_peri PERI_ADAI1 &clk_io IOBUS_DAI1>;
		clock-frequency = <11289600>;
		adma = <&adma1>;
		status = "disabled";
	};

	i2s2: i2s@76b01000 {
		compatible = "telechips,i2s";
		reg = <0x76b01000 0x50>;
		clocks = <&clk_peri PERI_ADAI2 &clk_io IOBUS_DAI2>;
		clock-frequency = <11289600>;
		adma = <&adma2>;
		status = "disabled";
	};

	i2s3: i2s@76101000 {
		compatible = "telechips,i2s";
		reg = <0x76101000 0x50>;
		clocks = <&clk_peri PERI_ADAI3 &clk_io IOBUS_DAI3>;
		clock-frequency = <11289600>;
		adma = <&adma3>;
		status = "disabled";
	};

	spdif0: spdif@76202000 {
		compatible = "telechips,spdif";
		reg = <0x76202000 0x1000>;
		clocks = <&clk_peri PERI_SPDIF0 &clk_io IOBUS_SPDIF0>;
		clock-frequency = <44100>;
		adma = <&adma0>;
		status = "disabled";
	};

	spdif1: spdif@76102000 {
		compatible = "telechips,spdif";
		reg = <0x76102000 0x6E0>;
		clocks = <&clk_peri PERI_SPDIF3 &clk_io IOBUS_SPDIF3>;
		clock-frequency = <44100>;
		adma = <&adma3>;
		status = "disabled";
	};

	cdif0: cdif@76201080 {
		compatible = "telechips,cdif";
		reg = <0x76201080 0x24>;
		clocks = <&clk_peri PERI_ADAM0>;
		clock-frequency = <44100>;
		adma = <&adma0>;
		status = "disabled";
	};

	cdif1: cdif@76101080 {
		compatible = "telechips,cdif";
		reg = <0x76101080 0x24>;
		clocks = <&clk_peri PERI_ADAM3>;
		clock-frequency = <44100>;
		adma = <&adma3>;
		status = "disabled";
	};

	i2c0: i2c@76300000 {
		compatible = "telechips,tcc897x-i2c";
		reg = <0x76300000 0x1c>,
			  <0x76360000 0x10>;
		interrupts = <GIC_SPI 38 IRQ_TYPE_LEVEL_HIGH>;
		#address-cells = <1>;
		#size-cells = <0>;
		clocks = <&clk_peri PERI_I2C0 &clk_io IOBUS_I2C_M0 &clk_fbus FBUS_IO>;
		clock-frequency = <400000>;
		port-mux = <0xFF>;
		status = "disabled";
		interrupt_mode = <0>;
	};

	i2c1: i2c@76310000 {
		compatible = "telechips,tcc897x-i2c";
		reg = <0x76310000 0x1c>,
			  <0x76360000 0x10>;
		interrupts = <GIC_SPI 38 IRQ_TYPE_LEVEL_HIGH>;
		#address-cells = <1>;
		#size-cells = <0>;
		clocks = <&clk_peri PERI_I2C1 &clk_io IOBUS_I2C_M1 &clk_fbus FBUS_IO>;
		clock-frequency = <400000>;
		port-mux = <0xFF>;
		status = "disabled";
		interrupt_mode = <0>;
	};

	i2c2: i2c@76320000 {
		compatible = "telechips,tcc897x-i2c";
		reg = <0x76320000 0x1c>,
			  <0x76360000 0x10>;
		interrupts = <GIC_SPI 38 IRQ_TYPE_LEVEL_HIGH>;
		#address-cells = <1>;
		#size-cells = <0>;
		clocks = <&clk_peri PERI_I2C2 &clk_io IOBUS_I2C_M2 &clk_fbus FBUS_IO>;
		clock-frequency = <400000>;
		port-mux = <0xFF>;
		status = "disabled";
		interrupt_mode = <0>;
	};

	i2c3: i2c@76330000 {
		compatible = "telechips,tcc897x-i2c";
		reg = <0x76330000 0x1c>,
			  <0x76360000 0x10>;
		interrupts = <GIC_SPI 38 IRQ_TYPE_LEVEL_HIGH>;
		#address-cells = <1>;
		#size-cells = <0>;
		clocks = <&clk_peri PERI_I2C3 &clk_io IOBUS_I2C_M3 &clk_fbus FBUS_IO>;
		clock-frequency = <400000>;
		port-mux = <0xFF>;
		status = "disabled";
		interrupt_mode = <0>;
	};
	gpsb0: spi@76900000 {
		compatible = "telechips,tcc-spi";
		reg = <0x76900000 0x38>,
		      <0x76960000 0x10>,
		      <0x76970000 0x84>;
		interrupts = <GIC_SPI 36 IRQ_TYPE_LEVEL_HIGH>;
		clocks = <&clk_peri PERI_GPSB0 &clk_io IOBUS_GPSB0>;
		gpsb-id = <0>;
		status = "disabled";
	};

	gpsb1: spi@76910000 {
		compatible = "telechips,tcc-spi";
		reg = <0x76910000 0x38>,
		      <0x76960000 0x10>,
		      <0x76970000 0x84>;
		interrupts = <GIC_SPI 36 IRQ_TYPE_LEVEL_HIGH>;
		clocks = <&clk_peri PERI_GPSB1 &clk_io IOBUS_GPSB1>;
		gpsb-id = <1>;
		status = "disabled";
	};

	gpsb2: spi@76920000 {
		compatible = "telechips,tcc-spi";
		reg = <0x76920000 0x38>,
		      <0x76960000 0x10>,
		      <0x76970000 0x84>;
		interrupts = <GIC_SPI 36 IRQ_TYPE_LEVEL_HIGH>;
		clocks = <&clk_peri PERI_GPSB2 &clk_io IOBUS_GPSB2>;
		gpsb-id = <2>;
		status = "disabled";
	};

	adc: adc@76064000 {
		compatible = "telechips,adc";
		reg = <0x76064000 0x24>,
		      <0x7440000C 0x4>;
		clocks = <&clk_peri PERI_ADC &clk_io IOBUS_TSADC &clk_isoip_top ISOIP_TOP_TSADC>;
		clock-frequency = <12000000>;
		ckin-frequency  = <1000000>;
		adc-12bit-resolution;
		adc-delay = <150>;
		#io-channel-cells = <1>;
		status = "disabled";
	};

	firmware {
		optee {
			compatible = "linaro,optee-tz";
			method = "none";
		};
	};
};
